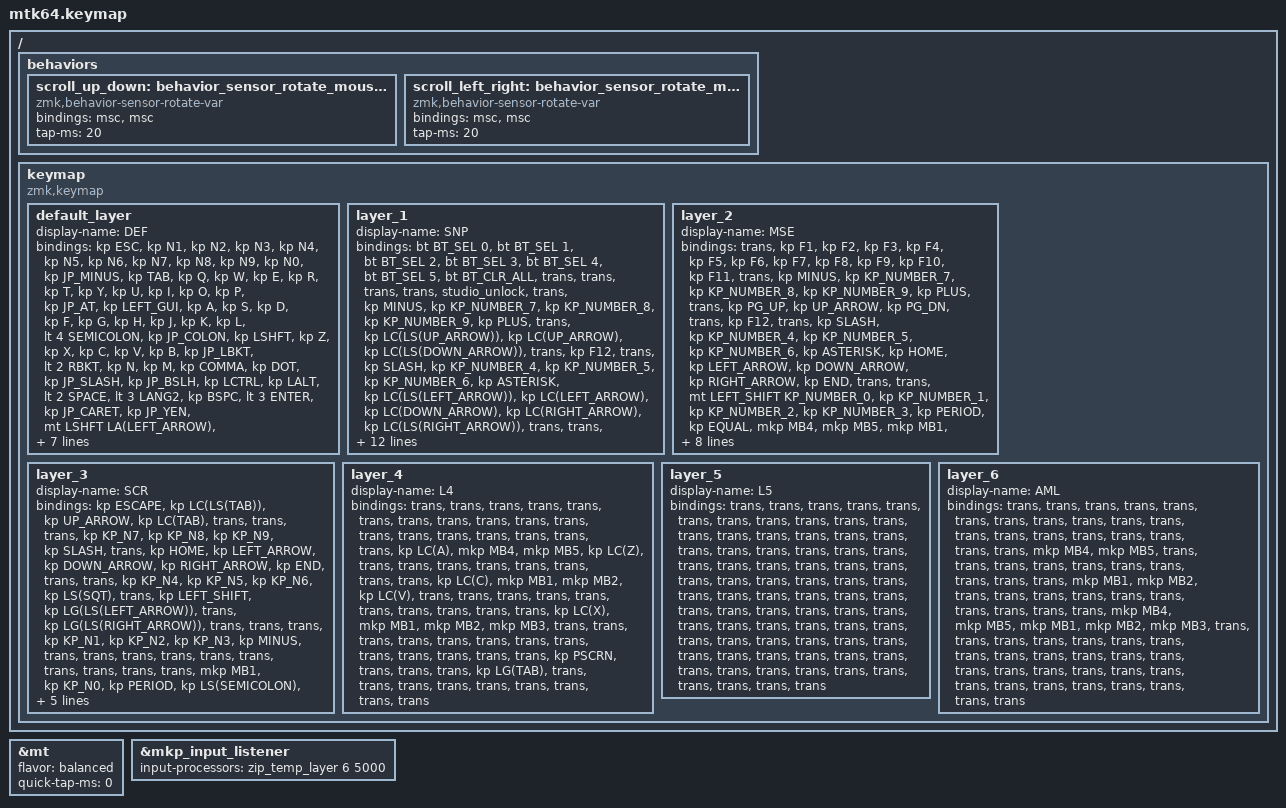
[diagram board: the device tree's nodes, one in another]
#include <input/processors.dtsi>
#include <behaviors.dtsi>
#include <dt-bindings/zmk/bt.h>
#include <dt-bindings/zmk/keys.h>
#include <dt-bindings/zmk/pointing.h>
#include "keycode_japanese.h"

// スクロール量の設定

#define ZMK_POINTING_DEFAULT_SCRL_VAL 100

&mt {
    flavor = "balanced";
    quick-tap-ms = <0>;
};

&mkp_input_listener { input-processors = <&zip_temp_layer 6 5000>; };

/ {
    behaviors {
        // 垂直スクロール用のbehaviorの設定

        scroll_up_down: behavior_sensor_rotate_mouse_wheel_up_down {
            compatible = "zmk,behavior-sensor-rotate-var";
            #sensor-binding-cells = <2>;
            bindings = <&msc>, <&msc>;

            tap-ms = <20>; // スクロールのタップ時間
        };

        // 水平スクロール用のbehaviorの設定

        scroll_left_right: behavior_sensor_rotate_mouse_wheel_left_right {
            compatible = "zmk,behavior-sensor-rotate-var";
            #sensor-binding-cells = <2>;
            bindings = <&msc>, <&msc>;

            tap-ms = <20>; // スクロールのタップ時間
        };
    };
};

/ {
    keymap {
        compatible = "zmk,keymap";

        default_layer {
            display-name = "DEF";
            bindings = <
&kp ESC  &kp N1  &kp N2  &kp N3  &kp N4  &kp N5  &kp N6  &kp N7  &kp N8  &kp N9  &kp N0  &kp JP_MINUS  &kp TAB  &kp Q  &kp W  &kp E  &kp R  &kp T  &kp Y  &kp U  &kp I  &kp O  &kp P  &kp JP_AT  &kp LEFT_GUI  &kp A  &kp S  &kp D  &kp F  &kp G  &kp H  &kp J  &kp K  &kp L  &lt 4 SEMICOLON  &kp JP_COLON  &kp LSHFT  &kp Z  &kp X  &kp C  &kp V  &kp B  &kp JP_LBKT  &lt 2 RBKT  &kp N  &kp M  &kp COMMA  &kp DOT  &kp JP_SLASH  &kp JP_BSLH  &kp LCTRL  &kp LALT  &lt 2 SPACE  &lt 3 LANG2  &kp BSPC  &lt 3 ENTER  &kp JP_CARET  &kp JP_YEN  &mt LSHFT LA(LEFT_ARROW)  &mt LSHFT LA(RIGHT_ARROW)  &lt 1 LANG4  &kp DEL  &kp ENTER  &tog 2  &lt 4 INT5  &mt LSHFT INT4  &mo 1  &mo 2  &mo 3  &mo 1  &mo 2  &mo 3  &mo 1  &mo 2  &mo 3
            >;

            sensor-bindings = <
                &inc_dec_kp LEFT_ARROW RIGHT_ARROW
                &inc_dec_kp UP_ARROW   DOWN_ARROW
            >;
        };

        layer_1 {
            display-name = "SNP";
            bindings = <
&bt BT_SEL 0  &bt BT_SEL 1  &bt BT_SEL 2  &bt BT_SEL 3  &bt BT_SEL 4  &bt BT_SEL 5  &bt BT_CLR_ALL  &trans  &trans  &trans  &trans  &studio_unlock  &trans  &kp MINUS  &kp KP_NUMBER_7  &kp KP_NUMBER_8  &kp KP_NUMBER_9  &kp PLUS  &trans  &kp LC(LS(UP_ARROW))  &kp LC(UP_ARROW)  &kp LC(LS(DOWN_ARROW))  &trans  &kp F12  &trans  &kp SLASH  &kp KP_NUMBER_4  &kp KP_NUMBER_5  &kp KP_NUMBER_6  &kp ASTERISK  &kp LC(LS(LEFT_ARROW))  &kp LC(LEFT_ARROW)  &kp LC(DOWN_ARROW)  &kp LC(RIGHT_ARROW)  &kp LC(LS(RIGHT_ARROW))  &trans  &trans  &mt LEFT_SHIFT KP_NUMBER_0  &kp KP_NUMBER_1  &kp KP_NUMBER_2  &kp KP_NUMBER_3  &kp PERIOD  &kp EQUAL  &mkp MB4  &mkp MB5  &mkp MB1  &mkp MB2  &mkp MB3  &trans  &trans  &trans  &trans  &trans  &trans  &trans  &trans  &trans  &trans  &kp C_MUTE  &kp C_BRI_MAX  &trans  &trans  &trans  &trans  &trans  &trans  &trans  &trans  &trans  &trans  &trans  &trans  &trans  &trans  &trans
            >;

            sensor-bindings =
                <&inc_dec_kp C_VOLUME_UP C_VOLUME_DOWN>,
                <&inc_dec_kp C_BRI_UP C_BRI_DEC>;
        };

        layer_2 {
            display-name = "MSE";
            bindings = <
&trans  &kp F1  &kp F2  &kp F3  &kp F4  &kp F5  &kp F6  &kp F7  &kp F8  &kp F9  &kp F10  &kp F11  &trans  &kp MINUS  &kp KP_NUMBER_7  &kp KP_NUMBER_8  &kp KP_NUMBER_9  &kp PLUS  &trans  &kp PG_UP  &kp UP_ARROW  &kp PG_DN  &trans  &kp F12  &trans  &kp SLASH  &kp KP_NUMBER_4  &kp KP_NUMBER_5  &kp KP_NUMBER_6  &kp ASTERISK  &kp HOME  &kp LEFT_ARROW  &kp DOWN_ARROW  &kp RIGHT_ARROW  &kp END  &trans  &trans  &mt LEFT_SHIFT KP_NUMBER_0  &kp KP_NUMBER_1  &kp KP_NUMBER_2  &kp KP_NUMBER_3  &kp PERIOD  &kp EQUAL  &mkp MB4  &mkp MB5  &mkp MB1  &mkp MB2  &mkp MB3  &trans  &trans  &trans  &trans  &trans  &trans  &trans  &trans  &trans  &trans  &trans  &trans  &trans  &trans  &trans  &trans  &trans  &trans  &trans  &trans  &trans  &trans  &trans  &trans  &trans  &trans  &trans
            >;

            sensor-bindings =
                <&inc_dec_kp LA(TAB) LS(LA(TAB))>,
                <&inc_dec_kp LC(PG_UP) LC(PG_DN)>;
        };

        layer_3 {
            display-name = "SCR";
            bindings = <
&kp ESCAPE  &kp LC(LS(TAB))  &kp UP_ARROW  &kp LC(TAB)  &trans  &trans  &trans  &kp KP_N7  &kp KP_N8  &kp KP_N9  &kp SLASH  &trans  &kp HOME  &kp LEFT_ARROW  &kp DOWN_ARROW  &kp RIGHT_ARROW  &kp END  &trans  &trans  &kp KP_N4  &kp KP_N5  &kp KP_N6  &kp LS(SQT)  &trans  &kp LEFT_SHIFT  &kp LG(LS(LEFT_ARROW))  &trans  &kp LG(LS(RIGHT_ARROW))  &trans  &trans  &trans  &kp KP_N1  &kp KP_N2  &kp KP_N3  &kp MINUS  &trans  &trans  &trans  &trans  &trans  &trans  &trans  &trans  &trans  &trans  &mkp MB1  &kp KP_N0  &kp PERIOD  &kp LS(SEMICOLON)  &kp LS(MINUS)  &trans  &trans  &trans  &trans  &trans  &trans  &trans  &trans
            >;

            sensor-bindings =
                <&inc_dec_kp LA(TAB) LS(LA(TAB))>,
                <&inc_dec_kp LC(PG_UP) LC(PG_DN)>;
        };

        layer_4 {
            display-name = "L4";
            bindings = <
&trans  &trans  &trans  &trans  &trans  &trans  &trans  &trans  &trans  &trans  &trans  &trans  &trans  &trans  &trans  &trans  &trans  &trans  &kp LC(A)  &mkp MB4  &mkp MB5  &kp LC(Z)  &trans  &trans  &trans  &trans  &trans  &trans  &trans  &trans  &kp LC(C)  &mkp MB1  &mkp MB2  &kp LC(V)  &trans  &trans  &trans  &trans  &trans  &trans  &trans  &trans  &trans  &trans  &kp LC(X)  &mkp MB1  &mkp MB2  &mkp MB3  &trans  &trans  &trans  &trans  &trans  &trans  &trans  &trans  &trans  &trans  &trans  &trans  &trans  &kp PSCRN  &trans  &trans  &trans  &kp LG(TAB)  &trans  &trans  &trans  &trans  &trans  &trans  &trans  &trans  &trans
            >;
        };

        layer_5 {
            display-name = "L5";
            bindings = <
&trans  &trans  &trans  &trans  &trans  &trans  &trans  &trans  &trans  &trans  &trans  &trans  &trans  &trans  &trans  &trans  &trans  &trans  &trans  &trans  &trans  &trans  &trans  &trans  &trans  &trans  &trans  &trans  &trans  &trans  &trans  &trans  &trans  &trans  &trans  &trans  &trans  &trans  &trans  &trans  &trans  &trans  &trans  &trans  &trans  &trans  &trans  &trans  &trans  &trans  &trans  &trans  &trans  &trans  &trans  &trans  &trans  &trans  &trans  &trans  &trans  &trans  &trans  &trans  &trans  &trans  &trans  &trans  &trans  &trans  &trans  &trans  &trans  &trans  &trans
            >;
        };

        layer_6 {
            display-name = "AML";
            bindings = <
&trans  &trans  &trans  &trans  &trans  &trans  &trans  &trans  &trans  &trans  &trans  &trans  &trans  &trans  &trans  &trans  &trans  &trans  &trans  &mkp MB4  &mkp MB5  &trans  &trans  &trans  &trans  &trans  &trans  &trans  &trans  &trans  &trans  &mkp MB1  &mkp MB2  &trans  &trans  &trans  &trans  &trans  &trans  &trans  &trans  &trans  &trans  &mkp MB4  &mkp MB5  &mkp MB1  &mkp MB2  &mkp MB3  &trans  &trans  &trans  &trans  &trans  &trans  &trans  &trans  &trans  &trans  &trans  &trans  &trans  &trans  &trans  &trans  &trans  &trans  &trans  &trans  &trans  &trans  &trans  &trans  &trans  &trans  &trans
            >;
        };
    };
};
